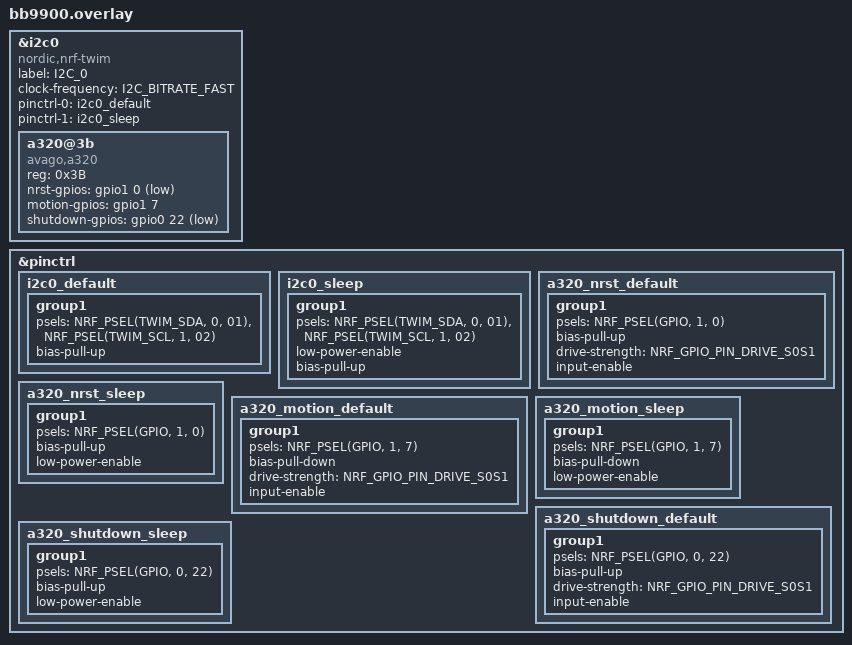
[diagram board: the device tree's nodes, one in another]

&i2c0 {
    a320@3b {
        compatible = "avago,a320";
        status = "okay";
        reg = <0x3B>;
        
        // A320控制引脚配置
        nrst-gpios = <&gpio1 0 GPIO_ACTIVE_LOW>;     // 复位引脚
        motion-gpios = <&gpio1 7 GPIO_ACTIVE_HIGH>;   // 移动检测引脚
        shutdown-gpios = <&gpio0 22 GPIO_ACTIVE_LOW>;  // 关机引脚
    };
    
    label = "I2C_0";
    compatible = "nordic,nrf-twim";
    status = "okay";
    clock-frequency = <I2C_BITRATE_FAST>; 
    pinctrl-0 = <&i2c0_default>;
    pinctrl-1 = <&i2c0_sleep>;
    pinctrl-names = "default", "sleep";
};

&pinctrl {
    i2c0_default: i2c0_default {
        group1 {
            psels = <NRF_PSEL(TWIM_SDA, 0, 01)>,
                <NRF_PSEL(TWIM_SCL, 1, 02)>;
            bias-pull-up;
        };
    };
    
    i2c0_sleep: i2c0_sleep {
        group1 {
            psels = <NRF_PSEL(TWIM_SDA, 0, 01)>,  // 修正：使用与默认状态相同的引脚
                <NRF_PSEL(TWIM_SCL, 1, 02)>;
            low-power-enable;
            bias-pull-up;
        };
    };
    
    // A320控制引脚的pinctrl配置
    a320_nrst_default: a320_nrst_default {
        group1 {
            psels = <NRF_PSEL(GPIO, 1, 0)>;  // 与nrst-gpios对应
            bias-pull-up;
            drive-strength = <NRF_GPIO_PIN_DRIVE_S0S1>;
            input-enable;
        };
    };
    
    a320_nrst_sleep: a320_nrst_sleep {
        group1 {
            psels = <NRF_PSEL(GPIO, 1, 0)>;  // 修正：使用与默认状态相同的引脚
            bias-pull-up;
            low-power-enable;
        };
    };
    
    a320_motion_default: a320_motion_default {
        group1 {
            psels = <NRF_PSEL(GPIO, 1, 7)>;  // 与motion-gpios对应
            bias-pull-down;
            drive-strength = <NRF_GPIO_PIN_DRIVE_S0S1>;
            input-enable;
        };
    };
    
    a320_motion_sleep: a320_motion_sleep {
        group1 {
            psels = <NRF_PSEL(GPIO, 1, 7)>;  // 修正：使用与默认状态相同的引脚
            bias-pull-down;
            low-power-enable;
        };
    };
    
    a320_shutdown_default: a320_shutdown_default {
        group1 {
            psels = <NRF_PSEL(GPIO, 0, 22)>;  // 修正：与shutdown-gpios对应
            bias-pull-up;
            drive-strength = <NRF_GPIO_PIN_DRIVE_S0S1>;
            input-enable;
        };
    };
    
    a320_shutdown_sleep: a320_shutdown_sleep {
        group1 {
            psels = <NRF_PSEL(GPIO, 0, 22)>;  // 修正：使用与默认状态相同的引脚
            bias-pull-up;
            low-power-enable;
        };
    };
};
